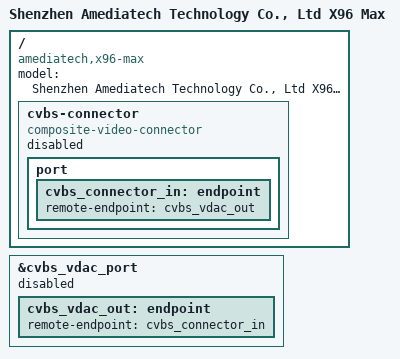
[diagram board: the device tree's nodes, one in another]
// SPDX-License-Identifier: (GPL-2.0+ OR MIT)
/*
 * Copyright (c) 2018 BayLibre SAS. All rights reserved.
 */

/dts-v1/;

#include "meson-g12a-x96-max.dts"

/ {
	compatible = "amediatech,x96-max", "amlogic,u200", "amlogic,g12a";
	model = "Shenzhen Amediatech Technology Co., Ltd X96 Max";

	cvbs-connector {
		status = "disable";
		compatible = "composite-video-connector";

		port {
			cvbs_connector_in: endpoint {
				remote-endpoint = <&cvbs_vdac_out>;
			};
		};
	};

};

&cvbs_vdac_port {
	status = "disable";
	cvbs_vdac_out: endpoint {
		remote-endpoint = <&cvbs_connector_in>;
	};
};
